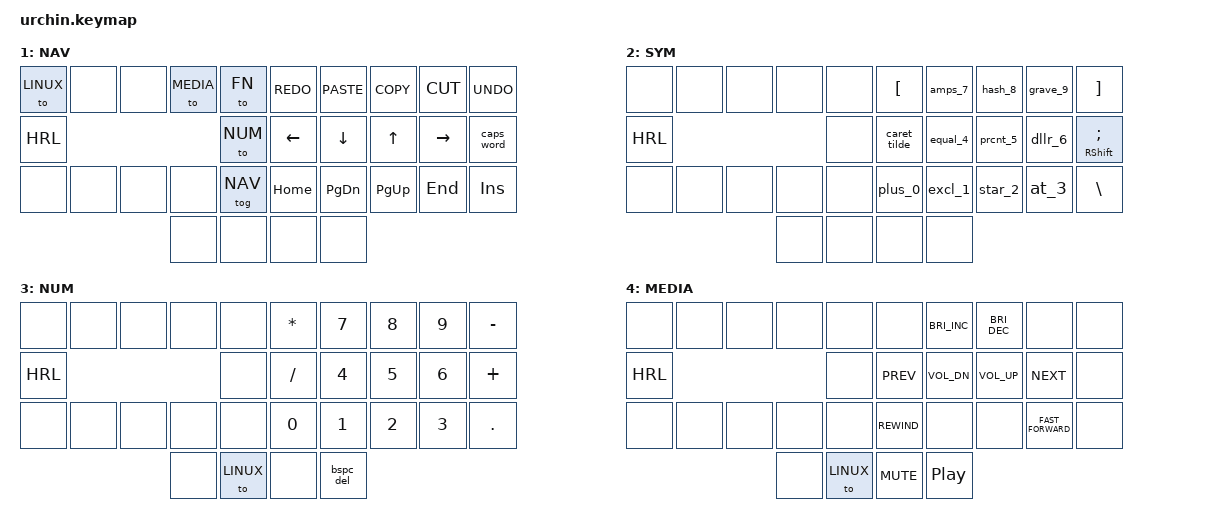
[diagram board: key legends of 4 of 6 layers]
/*
 * Copyright (c) 2020 duckyb
 *
 * SPDX-License-Identifier: MIT
 */

/*                KEY POSITIONS
      ╭─────────────────────╮ ╭─────────────────────╮
      │ 00  01  02  03  04  │ │ 05  06  07  08  09  │
      │ 10  11  12  13  14  │ │ 15  16  17  18  19  │
      │ 20  21  22  23  24  │ │ 25  26  27  28  29  │
      ╰───────╮     30  31  │ │ 32  33      ╭───────╯
              ╰─────────────╯ ╰─────────────╯ */


#include <behaviors.dtsi>
#include <dt-bindings/zmk/keys.h>
#include <dt-bindings/zmk/bt.h>
#include <dt-bindings/zmk/outputs.h>
#include <dt-bindings/zmk/pointing.h>

// Layer definitions
#define LINUX   0
#define NAV     1
#define SYM     2
#define NUM     3
#define MEDIA   4
#define FN      5

#define XXX &none

// -----------------------------------------------------------------------------------------
// define Layer-tap
#define LTS(k1)   &lt SYM k1
#define LTN(k1)   &lt NAV k1
#define LTNUM(k1) &lt NUM k1
#define LTM(k1)   &lt MEDIA k1
#define LTF(k1)   &lt FN k1
// -----------------------------------------------------------------------------------------
// define Home-row modifiers
#define HRML(k1,k2,k3,k4) &kp k1 &ht LCTRL k2 &ht LALT k3 &ht LMETA  k4
#define HRMR(k1,k2,k3,k4) &ht RMETA  k1 &ht RALT  k2 &ht RCTRL  k3 &kp k4
#define HRL &kp LSHIFT &kp LCTRL &kp LALT &kp LMETA
#define HRR &kp RMETA &kp RALT &kp RCTRL &kp RSHIFT


// -----------------------------------------------------------------------------------------

// define Hold-tap properties
#define TAPPING_TERM_MS 175
#define QUICK_TAP_MS 150

// define Combos properties
#define TIMEOUT_MS 40
#define TIMEOUT_MS_SLOW 100

// -----------------------------------------------------------------------------------------
&sk {
    // don't release mods on other mods presses
    ignore-modifiers;
    release-after-ms = <500>;
    quick-release;
};
// -----------------------------------------------------------------------------------------

// define Hold-tap properties
#define TAPPING_TERM_MS 175
#define QUICK_TAP_MS 150

// define Combos properties
#define TIMEOUT_MS 40
#define TIMEOUT_MS_SLOW 100

// -----------------------------------------------------------------------------------------


// -----------------------------------------------------------------------------------------
/ {
// -----------------------------------------------------------------------------------------
        behaviors {
// -----------------------------------------------------------------------------------------
        ht: hold_tap {
            label = "hold_tap";
            compatible = "zmk,behavior-hold-tap";
            #binding-cells = <2>;
            flavor = "tap-preferred";
            tapping-term-ms = <TAPPING_TERM_MS>;
            quick-tap-ms = <QUICK_TAP_MS>;
            global-quick-tap;
            bindings = <&kp>, <&kp>;
        };

// -----------------------------------------------------------------------------------------

        bspc_del: backspace_delete {
            compatible = "zmk,behavior-mod-morph";
            label = "BACKSPACE_DELETE";
            #binding-cells = <0>;
            bindings = <&kp BACKSPACE>, <&kp DELETE>;
            mods = <(MOD_LSFT|MOD_RSFT)>;
            keep-mods = <(MOD_RSFT)>;
        };
        htbd: ht_bspc_del {
            label = "hold_tap_bspc_del";
            compatible = "zmk,behavior-hold-tap";
            #binding-cells = <2>;
            flavor = "tap-preferred";
            tapping-term-ms = <TAPPING_TERM_MS>;
            quick-tap-ms = <QUICK_TAP_MS>;
            global-quick-tap;
            bindings = <&mo>, <&bspc_del>;
        };

        lpar_rpar: lpar_rpar {
            compatible = "zmk,behavior-mod-morph";
            label = "LPAR_RPAR";
            #binding-cells = <0>;
            bindings = <&kp LPAR>, <&kp RPAR>;
            mods = <(MOD_LSFT|MOD_RSFT)>;
            keep-mods = <(MOD_RSFT)>;
        };

        lbrc_rbrc: lbrc_rbrc {
            compatible = "zmk,behavior-mod-morph";
            label = "LBRC_RBRC";
            #binding-cells = <0>;
            bindings = <&kp LBRC>, <&kp RBRC>;
            mods = <(MOD_LSFT|MOD_RSFT)>;
            keep-mods = <(MOD_RSFT)>;
        };

        lbkt_rbkt: lbkt_rbkt {
            compatible = "zmk,behavior-mod-morph";
            label = "LBKT_RBKT";
            #binding-cells = <0>;
            bindings = <&kp LBKT>, <&kp RBKT>;
            mods = <(MOD_LSFT|MOD_RSFT)>;
            keep-mods = <(MOD_RSFT)>;
        };
// -----------------------------------------------------------------------------------------
        htst: ht_space_tab {
            label = "hold_tap_space_tab";
            compatible = "zmk,behavior-hold-tap";
            #binding-cells = <2>;
            flavor = "tap-preferred";
            tapping-term-ms = <TAPPING_TERM_MS>;
            quick-tap-ms = <QUICK_TAP_MS>;
            global-quick-tap;
            bindings = <&mo>, <&space_tab>;
        };
        space_tab: space_tab {
            compatible = "zmk,behavior-mod-morph";
            label = "SPACE_TAB";
            #binding-cells = <0>;
            bindings = <&kp SPACE>, <&kp TAB>;
            mods = <(MOD_LSFT|MOD_RSFT)>;
            keep-mods = <(MOD_RSFT)>;
        };

        htest: ht_esc_stab {
            label = "hold_tap_esc_stab";
            compatible = "zmk,behavior-hold-tap";
            #binding-cells = <2>;
            flavor = "tap-preferred";
            tapping-term-ms = <TAPPING_TERM_MS>;
            quick-tap-ms = <QUICK_TAP_MS>;
            global-quick-tap;
            bindings = <&mo>, <&esc_stab>;
        };
        esc_stab: esc_stab {
            compatible = "zmk,behavior-mod-morph";
            label = "ESC_STAB";
            #binding-cells = <0>;
            bindings = <&kp ESC>, <&kp LS(TAB)>;
            mods = <(MOD_LSFT|MOD_RSFT)>;
            keep-mods = <(MOD_RSFT)>;
        };
    };
// -----------------------------------------------------------------------------------------
// MORPH NUM LAYER
        excl_1: excl_1 {
            compatible = "zmk,behavior-mod-morph";
            label = "EXCL_1";
            #binding-cells = <0>;
            bindings = <&kp EXCL>, <&kp N1>;
            mods = <(MOD_LSFT|MOD_RSFT)>;
            keep-mods = <(MOD_RSFT)>;
        };
        star_2: star_2 {
            compatible = "zmk,behavior-mod-morph";
            label = "STAR_1";
            #binding-cells = <0>;
            bindings = <&kp STAR>, <&kp N2>;
            mods = <(MOD_LSFT|MOD_RSFT)>;
            keep-mods = <(MOD_RSFT)>;
        };
        at_3: at_3 {
            compatible = "zmk,behavior-mod-morph";
            label = "AT_3";
            #binding-cells = <0>;
            bindings = <&kp AT>, <&kp N3>;
            mods = <(MOD_LSFT|MOD_RSFT)>;
            keep-mods = <(MOD_RSFT)>;
        };
        equal_4: equal_4 {
            compatible = "zmk,behavior-mod-morph";
            label = "EQUAL_4";
            #binding-cells = <0>;
            bindings = <&kp EQUAL>, <&kp N4>;
            mods = <(MOD_LSFT|MOD_RSFT)>;
            keep-mods = <(MOD_RSFT)>;
        };
        prcnt_5: prcnt_5 {
            compatible = "zmk,behavior-mod-morph";
            label = "PRCNT_5";
            #binding-cells = <0>;
            bindings = <&kp PRCNT>, <&kp N5>;
            mods = <(MOD_LSFT|MOD_RSFT)>;
            keep-mods = <(MOD_RSFT)>;
        };
        dllr_6: dllr_6 {
            compatible = "zmk,behavior-mod-morph";
            label = "DLLR_6";
            #binding-cells = <0>;
            bindings = <&kp DLLR>, <&kp N6>;
            mods = <(MOD_LSFT|MOD_RSFT)>;
            keep-mods = <(MOD_RSFT)>;
        };
        amps_7: amps_7 {
            compatible = "zmk,behavior-mod-morph";
            label = "AMPS_7";
            #binding-cells = <0>;
            bindings = <&kp AMPS>, <&kp N7>;
            mods = <(MOD_LSFT|MOD_RSFT)>;
            keep-mods = <(MOD_RSFT)>;
        };
        hash_8: hash_8 {
            compatible = "zmk,behavior-mod-morph";
            label = "HASH_8";
            #binding-cells = <0>;
            bindings = <&kp HASH>, <&kp N8>;
            mods = <(MOD_LSFT|MOD_RSFT)>;
            keep-mods = <(MOD_RSFT)>;
        };
        grave_9: grave_9 {
            compatible = "zmk,behavior-mod-morph";
            label = "GRAVE_9";
            #binding-cells = <0>;
            bindings = <&kp GRAVE>, <&kp N9>;
            mods = <(MOD_LSFT|MOD_RSFT)>;
            keep-mods = <(MOD_RSFT)>;
        };
//       lpar_rpar: lpar_rpar {
//           compatible = "zmk,behavior-mod-morph";
//           label = "LPAR_RPAR";
//           #binding-cells = <0>;
//           bindings = <&kp LPAR>, <&kp RPAR>;
//           mods = <(MOD_LSFT|MOD_RSFT)>;
//           keep-mods = <(MOD_RSFT)>;
//       };
        plus_0: plus_0 {
            compatible = "zmk,behavior-mod-morph";
            label = "PLUS_0";
            #binding-cells = <0>;
            bindings = <&kp PLUS>, <&kp N0>;
            mods = <(MOD_LSFT|MOD_RSFT)>;
            keep-mods = <(MOD_RSFT)>;
        };
        caret_tilde: caret_tilde {
            compatible = "zmk,behavior-mod-morph";
            label = "CARET_TILDE";
            #binding-cells = <0>;
            bindings = <&kp CARET>, <&kp TILDE>;
            mods = <(MOD_LSFT|MOD_RSFT)>;
            keep-mods = <(MOD_RSFT)>;
        };


// -----------------------------------------------------------------------------------------
        macros {
// -----------------------------------------------------------------------------------------
        thumb_tap: thumb_tap {
            label = "thumb_tap";
            compatible = "zmk,behavior-macro";
            #binding-cells = <0>;
            bindings
                = <&macro_press &kp TAB>
                , <&macro_tap &kp Z &kp M &kp K>
                , <&macro_release &kp TAB>
                ;
        };

        pscrn_custom: pscrn_custom {
            label = "pscrn_custom";
            compatible = "zmk,behavior-macro";
            #binding-cells = <0>;
            bindings
                = <&kp PSCRN>
                , <&to LINUX>
                ;
        };
    };

// -----------------------------------------------------------------------------------------
        combos {
// -----------------------------------------------------------------------------------------
        compatible = "zmk,combos";

// COMBOS LEFT
        combo_ctlA {
            timeout-ms = <TIMEOUT_MS>;
            key-positions = <10 11>;
            bindings = <&kp LC(A)>;
        };
        combo_esc {
            timeout-ms = <TIMEOUT_MS>;
            key-positions = <1 2>;
            bindings = <&kp ESC>;
        };
//       combo_repeat {
//           timeout-ms = <TIMEOUT_MS>;
//           key-positions = <1 2>;
//           bindings = <&key_repeat>;
//       };
        combo_lshift {
            timeout-ms = <TIMEOUT_MS>;
            key-positions = <11 12>;
            bindings = <&sk LSHIFT>;
        };
        combo_ret {
            timeout-ms = <TIMEOUT_MS>;
            key-positions = <12 13>;
            bindings = <&kp RET>;
        };
        combo_tab {
            timeout-ms = <TIMEOUT_MS>;
            key-positions = <1 2 3>;
            bindings = <&kp TAB>;
        };
//       combo_stab {
//           timeout-ms = <TIMEOUT_MS>;
//           key-positions = <4 05>;
//           bindings = <&kp LS(TAB)>;
//       };
        combo_at { // @
            timeout-ms = <TIMEOUT_MS>;
            key-positions = <1 11>;
            bindings = <&kp AT>;
        };
        combo_grave { // `
            timeout-ms = <TIMEOUT_MS>;
            key-positions = <11 21>;
            bindings = <&kp GRAVE>;
        };
        combo_hash {
            timeout-ms = <TIMEOUT_MS>;
            key-positions = <02 12>;
            bindings = <&kp HASH>;
        };
        combo_bslh {
            timeout-ms = <TIMEOUT_MS>;
            key-positions = <12 22>;
            bindings = <&kp BSLH>;
        };
        combo_amps { // &
            timeout-ms = <TIMEOUT_MS>;
            key-positions = <3 13>;
            bindings = <&kp AMPS>;
        };
        combo_pipe { // |
            timeout-ms = <TIMEOUT_MS>;
            key-positions = <13 23>;
            bindings = <&kp PIPE>;
        };
        combo_prcnt { // %
            timeout-ms = <TIMEOUT_MS>;
            key-positions = <4 14>;
            bindings = <&kp PRCNT>;
        };
        combo_tilde { // ~
            timeout-ms = <TIMEOUT_MS>;
            key-positions = <14 24>;
            bindings = <&kp TILDE>;
        };
//       combo_undo {
//           timeout-ms = <TIMEOUT_MS>;
//           key-positions = <16 17>;
//           bindings = <&kp LC(Z)>;
//       };
//       combo_redo {
//           timeout-ms = <TIMEOUT_MS>;
//           key-positions = <28 29>;
//           bindings = <&kp LC(LS(Z))>;
//       };
//       combo_z {
//           timeout-ms = <TIMEOUT_MS_SLOW>;
//           key-positions = <13 14>;
//           bindings = <&kp Z>;
//       };
        combo_copy {
            timeout-ms = <TIMEOUT_MS>;
            key-positions = <21 22>;
            bindings = <&kp LC(C)>;
        };
        combo_paste {
            timeout-ms = <TIMEOUT_MS>;
            key-positions = <22 23>;
            bindings = <&kp LC(V)>;
        };
        combo_cut {
            timeout-ms = <TIMEOUT_MS>;
            key-positions = <21 23>;
            bindings = <&kp LC(X)>;
        };
//       combo_caps {
//           timeout-ms = <TIMEOUT_MS_SLOW>;
//           key-positions = <16 19>;
//           bindings = <&caps_word>;
//       };

// COMBOS RIGHT
        combo_caret { // ^
            timeout-ms = <TIMEOUT_MS>;
            key-positions = <5 15>;
            bindings = <&kp CARET>;
        };
        combo_under { // _
            timeout-ms = <TIMEOUT_MS>;
            key-positions = <15 25>;
            bindings = <&kp UNDER>;
        };
        combo_plus { // +
            timeout-ms = <TIMEOUT_MS>;
            key-positions = <6 16>;
            bindings = <&kp PLUS>;
        };
        combo_minus { // -
            timeout-ms = <TIMEOUT_MS>;
            key-positions = <16 26>;
            bindings = <&kp MINUS>;
        };
        combo_lbrc {
            timeout-ms = <TIMEOUT_MS>;
            key-positions = <6 7>;
            bindings = <&lbrc_rbrc>;
        };
//       combo_rbrc {
//           timeout-ms = <TIMEOUT_MS>;
//           key-positions = <8 9>;
//           bindings = <&kp RBRC>;
//       };
        combo_lpar {
            timeout-ms = <TIMEOUT_MS>;
            key-positions = <16 17>;
            bindings = <&lpar_rpar>;
        };
        combo_rshift {
            timeout-ms = <TIMEOUT_MS>;
            key-positions = <17 18>;
            bindings = <&sk RSHIFT>;
        };
        combo_lbkt {
            timeout-ms = <TIMEOUT_MS>;
            key-positions = <26 27>;
            bindings = <&lbkt_rbkt>;
        };
//       combo_rbkt {
//           timeout-ms = <TIMEOUT_MS>;
//           key-positions = <32 33>;
//           bindings = <&kp RBKT>;
//       };
        combo_dllr {
            timeout-ms = <TIMEOUT_MS>;
            key-positions = <8 18>;
            bindings = <&kp DLLR>;
        };
        combo_equal {
            timeout-ms = <TIMEOUT_MS>;
            key-positions = <18 28>;
            bindings = <&kp EQUAL>;
        };
        combo_colon {
            timeout-ms = <TIMEOUT_MS>;
            key-positions = <7 8>;
            bindings = <&kp COLON>;
        };
        combo_semi {
            timeout-ms = <TIMEOUT_MS>;
            key-positions = <27 28>;
            bindings = <&kp SEMI>;
        };
        combo_star {
            timeout-ms = <TIMEOUT_MS>;
            key-positions = <7 17>;
            bindings = <&kp STAR>;
        };
        combo_fslh {
            timeout-ms = <TIMEOUT_MS>;
            key-positions = <17 27>;
            bindings = <&kp FSLH>;
        };
        combo_qmark {
            timeout-ms = <TIMEOUT_MS>;
            key-positions = <8 9>;
            bindings = <&kp QMARK>;
        };
        combo_excl {
            timeout-ms = <TIMEOUT_MS>;
            key-positions = <5 6>;
            bindings = <&kp EXCL>;
        };
        combo_to_nav {
            timeout-ms = <TIMEOUT_MS>;
            key-positions = <32 33>;
            bindings = <&to NAV>;
        };
    };
// -----------------------------------------------------------------------------------------
        keymap {
                compatible = "zmk,keymap";

// -----------------------------------------------------------------------------------------
                linux_layer {
// -----------------------------------------------------------------------------------------
                        label = "LINUX";
                        bindings = <
//   ╭──────────┬──────────┬──────────┬──────────┬──────────╮   ╭──────────┬──────────┬──────────┬──────────┬──────────╮
//   │  Q       │  W       │  E       │  R       │  T       │   │  Y       │  U       │  I       │  O       │  P       │
       &kp Q      &kp W      &kp E      &kp R      &kp T          &kp Y      &kp U      &kp I      &kp O      &kp P
//   ├──────────┼──────────┼──────────┼──────────┼──────────┤   ├──────────┼──────────┼──────────┼──────────┼──────────┤
//   │  A       │  S       │  D       │  F       │  G       │   │  H       │  J       │  K       │  L       │  ' "     │
      HRML(A,      S,         D,         F)         &kp G         &kp H      HRMR(J,     K,         L,         APOS)
//   ├──────────┼──────────┼──────────┼──────────┼──────────┤   ├──────────┼──────────┼──────────┼──────────┼──────────┤
//   │  Z       │  X       │  C       │  V       │  B       │   │  N       │  M       │  , <     │  . >     │  CAPS    │
       &kp Z      &kp X      &kp C      &kp V      &kp B          &kp N      &kp M      &kp COMMA  &kp DOT   &caps_word
//   ╰──────────┴──────────┴──────────┴──────────┴──────────╯   ╰──────────┴──────────┴──────────┴──────────┴──────────╯
//                               ╭─────────────┬────────────╮   ╭─────────────┬─────────────╮
//                               │ SPACE/NUM   │  NAV       │   │    X        │      X      │
                                   LTNUM(SPACE)   &mo NAV           XXX         &bspc_del
//                               ╰─────────────┴────────────╯   ╰─────────────┴─────────────╯
                     >;
             };

// --------------------------------------------------------------------------------------
             nav_layer {
// --------------------------------------------------------------------------------------
                     label = "NAV";
                     bindings = <
//   ╭──────────┬──────────┬──────────┬──────────┬──────────╮   ╭──────────┬──────────┬──────────┬──────────┬──────────╮
//   │  BASE    │   X      │   X      │  MEDIA   │  FN      │   │  REDO    │  PASTE   │  COPY    │  CUT     │  UNDO    │
       &to LINUX   XXX        XXX       &to MEDIA  &to FN        &kp K_REDO &kp K_PASTE &kp K_COPY &kp K_CUT &kp K_UNDO
//   ├──────────┼──────────┼──────────┼──────────┼──────────┤   ├──────────┼──────────┼──────────┼──────────┼──────────┤
//   │  LSHIFT  │  LCTRL   │  LALT    │  LMETA   │  NUM     │   │  LEFT    │  DOWN    │    UP    │  RIGHT   │  CAPS    │
         HRL                                       &to  NUM        &kp LEFT    &kp DOWN    &kp UP    &kp RIGHT &caps_word
//   ├──────────┼──────────┼──────────┼──────────┼──────────┤   ├──────────┼──────────┼──────────┼──────────┼──────────┤
//   │  X       │  X       │  X       │  X       │    X     │   │  HOME    │  PG_DN   │  PG_UP   │  END     │  INS     │
       XXX         XXX        XXX        XXX      &tog  NAV       &kp HOME   &kp PG_DN  &kp PG_UP   &kp END    &kp INS
//   ╰──────────┴──────────┴──────────┴──────────┴──────────╯   ╰──────────┴──────────┴──────────┴──────────┴──────────╯
//                                ╭─────────────┬────────────╮   ╭─────────────┬─────────────╮
//                                │      X      │      X     │   │     X       │     X       │
                                       XXX           XXX             XXX           XXX
//                                ╰─────────────┴────────────╯   ╰─────────────┴─────────────╯
                        >;
                };

// --------------------------------------------------------------------------------------
             sym_layer {
// --------------------------------------------------------------------------------------
                     label = "SYM";
                     bindings = <
//   ╭──────────┬──────────┬──────────┬──────────┬──────────╮   ╭──────────┬──────────┬──────────┬──────────┬──────────╮
//   │  X       │  X       │  X       │  X       │  X       │   │   [ {    │   & 7    │   # 8    │   ` 9    │   ] }    │
       XXX         XXX        XXX        XXX        XXX          &kp LBKT    &amps_7     &hash_8   &grave_9   &kp RBKT
//   ├──────────┼──────────┼──────────┼──────────┼──────────┤   ├──────────┼──────────┼──────────┼──────────┼──────────┤
//   │  LSHIFT  │  LCTRL   │  LALT    │  LMETA   │  X       │   │   ^ ~    │   = 4    │   % 5    │   6 $    │  ; :     │
         HRL                                        XXX         &caret_tilde  &equal_4   &prcnt_5   &dllr_6  &ht RSHIFT SEMI
//   ├──────────┼──────────┼──────────┼──────────┼──────────┤   ├──────────┼──────────┼──────────┼──────────┼──────────┤
//   │  X       │  X       │  X       │  X       │  X       │   │    + 0   │   ! 1    │   * 2    │   @ 3    │   \ |    │
       XXX         XXX        XXX        XXX        XXX            &plus_0    &excl_1   &star_2     &at_3     &kp BSLH
//   ╰──────────┴──────────┴──────────┴──────────┴──────────╯   ╰──────────┴──────────┴──────────┴──────────┴──────────╯
//                               ╭─────────────┬────────────╮   ╭─────────────┬─────────────╮
//                               │      X      │     X      │   │     X       │      X      │
                                       XXX         XXX              XXX           XXX
//                               ╰─────────────┴────────────╯   ╰─────────────┴─────────────╯
                     >;
             };
// --------------------------------------------------------------------------------------
             num_layer {
// --------------------------------------------------------------------------------------
                     label = "NUM";
                     bindings = <
//   ╭──────────┬──────────┬──────────┬──────────┬──────────╮   ╭──────────┬──────────┬──────────┬──────────┬──────────╮
//   │  X       │  X       │  X       │  X       │  X       │   │     *    │    7     │     8    │     9    │    -     │
       XXX         XXX        XXX        XXX        XXX           &kp STAR    &kp N7     &kp N8     &kp N9    &kp MINUS     
//   ├──────────┼──────────┼──────────┼──────────┼──────────┤   ├──────────┼──────────┼──────────┼──────────┼──────────┤
//   │  LSHIFT  │  LCTRL   │  LALT    │  LMETA   │  X       │   │     /    │    4     │     5    │     6    │    +     │
         HRL                                        XXX           &kp SLASH   &kp N4      &kp N5    &kp N6     &kp PLUS     
//   ├──────────┼──────────┼──────────┼──────────┼──────────┤   ├──────────┼──────────┼──────────┼──────────┼──────────┤
//   │  X       │  X       │  X       │  X       │  X       │   │     0    │    1     │     2    │     3    │    .     │
       XXX         XXX        XXX        XXX        XXX           &kp N0      &kp N1     &kp N2     &kp N3    &kp DOT       
//   ╰──────────┴──────────┴──────────┴──────────┴──────────╯   ╰──────────┴──────────┴──────────┴──────────┴──────────╯
//                               ╭─────────────┬────────────╮   ╭─────────────┬─────────────╮
//                               │      X      │    NAV     │   │     X       │      X      │
                                       XXX        &to LINUX          XXX        &bspc_del
//                               ╰─────────────┴────────────╯   ╰─────────────┴─────────────╯
                     >;
             };

// --------------------------------------------------------------------------------------
             media_layer {
// --------------------------------------------------------------------------------------
                     label = "MEDIA";
                     bindings = <
//   ╭──────────┬──────────┬──────────┬──────────┬──────────╮   ╭─────────────────┬──────────────────────┬─────────────────────┬────────────────┬────────────────╮
//   │  X       │  X       │  X       │  X       │  X       │   │       X         │          BRI_UP      │        BRI_DN       │       X        │      X         │
       XXX         XXX        XXX        XXX        XXX                XXX          &kp C_BRIGHTNESS_INC   &kp C_BRIGHTNESS_DEC       XXX             XXX
//   ├──────────┼──────────┼──────────┼──────────┼──────────┤   ├─────────────────┼──────────────────────┼─────────────────────┼────────────────┼────────────────┤
//   │  X       │  X       │  X       │  X       │  X       │   │      Prev       │       Vol down       │        Vol up       │      Next      │      X         │
       HRL                                          XXX              &kp C_PREV         &kp C_VOL_DN           &kp C_VOL_UP        &kp C_NEXT         XXX
//   ├──────────┼──────────┼──────────┼──────────┼──────────┤   ├─────────────────┼──────────────────────┼─────────────────────┼────────────────┼────────────────┤
//   │  X       │  X       │  X       │  X       │  X       │   │     REWIND      │           X          │           X         │      FFWD      │      X         │
       XXX         XXX        XXX        XXX        XXX             &kp C_REWIND             XXX                    XXX         &kp C_FAST_FORWARD    XXX
//   ╰──────────┴──────────┴──────────┴──────────┴──────────╯   ╰─────────────────┴──────────────────────┴─────────────────────┴────────────────┴────────────────╯
//                               ╭─────────────┬────────────╮   ╭────────────┬─────────────╮
//                               │    X        │    NAV     │   │  Mute      │  Play/Pause │
                                     XXX         &to LINUX        &kp C_MUTE     &kp C_PP
//                               ╰─────────────┴────────────╯   ╰─────────────┴────────────╯
                     >;
             };

// --------------------------------------------------------------------------------------
             fn_layer {
// --------------------------------------------------------------------------------------
                     label = "FN";
                     bindings = <
//   ╭──────────┬──────────┬──────────┬──────────┬──────────╮   ╭──────────────┬─────────────┬──────────────┬──────────────┬──────────────╮
//   │   F12    │    F7    │    F8    │    F9    │  PSCRN   │   │    BT_PRV    │   BT_PRV    │    BT_NXT    │   BT_NXT     │   BT_CLR     │
       &kp F12    &kp F7     &kp F8     &kp F9   &pscrn_custom     &bt BT_PRV    &bt BT_PRV     &bt BT_NXT     &bt BT_NXT     &bt BT_CLR
//   ├──────────┼──────────┼──────────┼──────────┼──────────┤   ├──────────────┼─────────────┼──────────────┼──────────────┼──────────────┤
//   │   F11    │    F4    │    F5    │    F6    │  NUMLOCK │   │   BEHAVIOR   │    RMETA    │    RALT      │     RCTRL    │   RSHIFT     │
       &kp F11    &kp F4     &kp F5     &kp F6   &kp KP_NLCK      &out OUT_TOG    &kp RMETA      &kp RALT      &kp RCTRL     &kp RSHIFT
//   ├──────────┼──────────┼──────────┼──────────┼──────────┤   ├──────────────┼─────────────┼──────────────┼──────────────┼──────────────┤
//   │   F10    │    F1    │    F2    │    F3    │  BREAK   │   │   BT_SEL 1   │  BT_SEL 2   │   BT_SEL 3   │   BT_SEL 4   │   BT_SEL 5   │
       &kp F10    &kp F1     &kp F2     &kp F3  &kp PAUSE_BREAK   &bt BT_SEL 0   &bt BT_SEL 1   &bt BT_SEL 2  &bt BT_SEL 3    &bt BT_SEL 4
//   ╰──────────┴──────────┴──────────┴──────────┴──────────╯   ╰──────────────┴─────────────┴──────────────┴──────────────┴──────────────╯
//                               ╭─────────────┬────────────╮   ╭─────────────┬─────────────╮
//                               │      X      │    NAV     │   │     X       │      X      │
                                       XXX         &to LINUX         XXX            XXX
//                               ╰─────────────┴────────────╯   ╰─────────────┴─────────────╯
                     >;
             };

// -----------------------------------------------------------------------------------------
        };
};
